# RL6842_IP_SVD register map
Vendor: Realtek
IP svd file
Registers are 32-bit, read-write, reset 0x0 unless marked. A register's access mark holds for its fields unless they carry their own. Offsets are from the block's base; lines under a group give offsets from that group; [hi:lo] are bit positions; {n}, {i} and the like mark numbered series; 'fields as' and 'values as' point back to an identical list; <NAME> marks a mode.

## Memory map
0x40000000 PAGE0 size 0x100
0x40000000 PAGE1 size 0x1200
0x40000000 PAGE2 size 0x300
0x40000000 PAGE3 size 0x1310
0x40000000 PAGE4 size 0x14A4
0x40000000 PAGE5 size 0x15AC
0x40000000 PAGE6 size 0x1700
0x40000000 PAGE7 size 0x800
0x40000000 PAGE12 size 0x1300
0x40000000 PAGE17 size 0x1800
0x40000000 PAGE26 size 0x2620
0x40000000 TXPWR_CTRL size 0xDB04
0x40100000 AES_REG size 0x101C
0x40108000 SHA_REG size 0x101C
0x40110000 GDMA0_REG size 0x400
0x40118000 SPI0_REG size 0xB0C
0x40119000 SPI1_REG size 0xB0C
0x4011A000 I2C0_REG size 0x100
0x4011B000 I2C1_REG size 0x100
0x4011C000 SPORT0_REG size 0x984
0x4011D000 SPORT1_REG size 0x984
0x4011E000 DEBUGTIMER_REG size 0x18
0x4011F000 ECDSA_REG size 0x204
0x41000000 OTPC_REG size 0x744
0x41008000 PSRAM_PHY_REG size 0xFC
0x41009000 PSRAM_REG size 0x1D4
0x4100A000 SPI_FLASH_CTRL size 0x1D4
0x4100C000 LP_AON size 0x100
0x4100C100 REGU size 0x80
0x4100C200 LP_SYS size 0x100
0x4100C300 PMC size 0x64
0x4100C400 XTAL size 0x40
0x4100C440 PLL size 0x38
0x4100C480 WLAFE size 0x40
0x4100C600 MEMX size 0x200
0x4100C800 PINMUX_REG size 0x1FC
0x4100CA00 RSIP_REG size 0x160
0x4100CC00 WDG0_REG size 0x14
0x41010000 UART0_REG size 0x60
0x41011000 UART1_REG size 0x60
0x41012000 UART2_REG size 0x60
0x41013000 UART3_REG size 0x60
0x41014000 UARTLOG_REG size 0x78
0x41015000 LEDC_REG size 0xF8
0x41016000 TRNG_REG size 0x1BC
0x41017000 AUDIO_REG size 0x908
{0x41018000+0x200*n} TIMER{n}_REG size 0x88 (n=0..14)
0x4101A000 GPIO_REG size 0x100
0x4101B000 RTC size 0x2C
0x4101C000 ADC_REG size 0xB4
0x4101C800 CMP_REG size 0x58
0x4101D000 THERMAL_REG size 0x34
0x4101E000 CTC_REG size 0x418
0x4101F000 WDG1_REG size 0x14
0x4101F040 WDG2_REG size 0x14
0x4101F080 WDG3_REG size 0x14
0x4101F0C0 WDG4_REG size 0x14
0x41020000 IPC0_REG size 0x28
0x41020080 IPC1_REG size 0x28
0x41020100 IPC2_REG size 0x28
0x41021000 SDM_REG size 0x24
0x41022100 AUD_SYS_REG size 0x30
0x42000000 ZGB size 0x28

## SDM_REG
Base 0x41021000
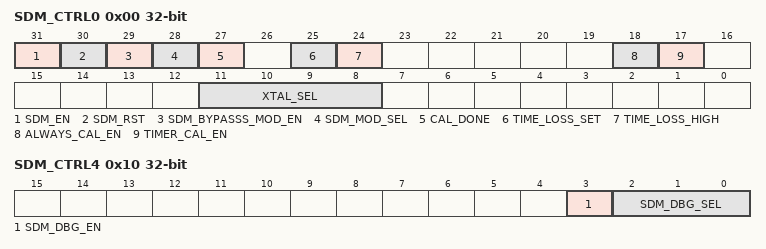
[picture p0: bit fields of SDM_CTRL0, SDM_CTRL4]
0x00 SDM_CTRL0 access per field — SDM Control Register
  [31] SDM_EN rw — Enable SDM
  [30] SDM_RST rw — 0: Reset SDM
  [29] SDM_BYPASSS_MOD_EN rw — Bypass mode enable
  [28] SDM_MOD_SEL rw — 0: Default mode 1: User-defined parameter mode
  [27] CAL_DONE ro
  [25] TIME_LOSS_SET rw — Time loss set 1: User-defined
  [24] TIME_LOSS_HIGH rw — Decide 32k output compensation direction 1: Mask 0: Add
  [18] ALWAYS_CAL_EN rw — 1: Enable always_cal
  [17] TIMER_CAL_EN rw — 1: Enable timer_cal
  [11:8] XTAL_SEL rw — XTAL frequency select, default 40M * 4'h0: XTAL40M * 4'h1: XTAL25M * 4'h4: XTAL20M * 4'h5: XTAL26M * 4'hD: XTAL27M * 4'hE: XTAL24M
0x04 SDM_CTRL1 — Config observed 128K cycle
  [15:0] SDM_OBS_CYC — Set observed 128k cycle, default 1024 128k cycles
0x08 SDM_CTRL2 — Set ref counter value
  [31:0] SDM_OBS_REF_CYC — Set in observed cycles, refer to counters value, default 312500 XTAL cycles
0x0C SDM_CTRL3 — Set XTAL period
  [31:0] XTAL_PERIOD — Set reference xtal period (ns)
0x10 SDM_CTRL4 — SDM Debug Register
  [3] SDM_DBG_EN — 1: Enable SDM debug
  [2:0] SDM_DBG_SEL — Set in observed cycles, refer to counters value
0x14 SDM_CTRL5 — Time loss Set
  [31:0] TIME_LOSS_REG — Source clock time loss every cycle
0x1C SDM_TIMEOUT reset 0x2000000 — Set Timer Trigger Counter Value
  [31:0] TIMEOUT_CNT — Set SDM timer trigger calibration timeout value
0x20 REG_SDM_DUMMY reset 0xFFFF — SDM Dummy Register

## PSRAM_PHY_REG
Base 0x41008000
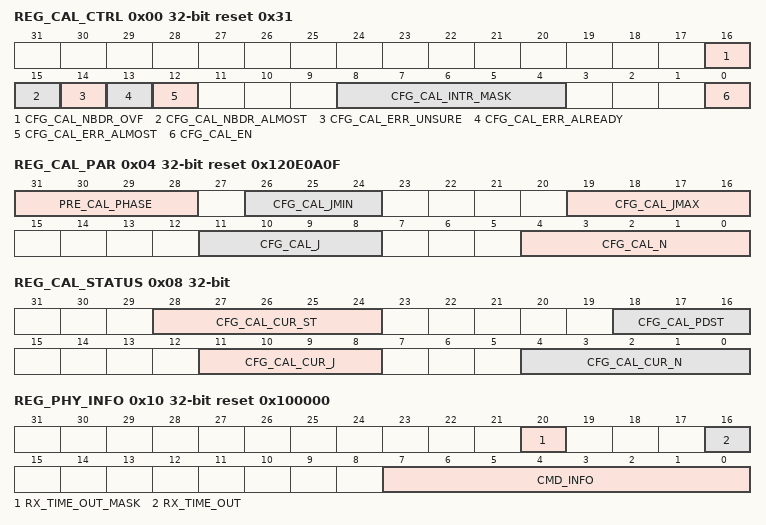
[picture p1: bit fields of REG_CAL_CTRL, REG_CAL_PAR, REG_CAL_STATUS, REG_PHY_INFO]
0x00 REG_CAL_CTRL access per field reset 0x31
  [16] CFG_CAL_NBDR_OVF ro — The N reachs the boundary , which is 0 or Nmax . Cleared by write 1 .
  [15] CFG_CAL_NBDR_ALMOST ro — The N-J or N+J reachs the boundary , which is 0 or Nmax . Cleared by write 1 .
  [14] CFG_CAL_ERR_UNSURE ro — The Pre N/J may cause current burst receive error , but it is not sure because the burst len is too small. Cleared by write 1 .
  [13] CFG_CAL_ERR_ALREADY ro — The Pre N/J may cause current burst receive error , even change J to Jmin , the error still remain . Cleared by write 1 .
  [12] CFG_CAL_ERR_ALMOST ro — The current burst receive correct , but next burst will set J = Jmin . Cleared by write 1 .
  [8:4] CFG_CAL_INTR_MASK rw — Calibration fail interrupt mask , every bit control one event above (1: enable , 0: disable) [0] : err almost [1] : err already [2] : err unsure [3] : nbdr almost [4] : nbdr ovf
  [0] CFG_CAL_EN rw — Hardware auto calibration enable , if disable , N,J will be fixed .
0x04 REG_CAL_PAR reset 0x120E0A0F
  [31:28] PRE_CAL_PHASE — one-hot phase select, 4-tap delay line to adjust rwds phase before calibration for large freq range or skew can be set to 0, bypassing the default 1-tap delay
  [26:24] CFG_CAL_JMIN — Minimum J . Hardware may adjust J , if J reach this value , an interrup will be raised to alerm software.
  [19:16] CFG_CAL_JMAX — Maximum J . Hardware may adjust J , but will not exceed this value.
  [11:8] CFG_CAL_J — Initial value J calibrated by software .
  [4:0] CFG_CAL_N — Initial value N calibrated by software .
0x08 REG_CAL_STATUS ro
  [28:24] CFG_CAL_CUR_ST — Calibration current state . Cleared by write all 1 .
  [18:16] CFG_CAL_PDST — Calibration check result for last read burst . [0] : indicate phase n+j , if 1 , means dn == dn+j [1] : indicate phase n-j , if 1 , means dn == dn-j [2] : if 1 , means the state is under j = jmin condition
  [11:8] CFG_CAL_CUR_J — Current value J read from hardware.
  [4:0] CFG_CAL_CUR_N — Current value N read from hardware.
0x10 REG_PHY_INFO access per field reset 0x100000
  [20] RX_TIME_OUT_MASK rw — read time out interrupt mask
  [16] RX_TIME_OUT ro — read time out interrupt if there's no DQS/DQ from psram, write 1 to clear
  [7:0] CMD_INFO ro — Command information, 1st Byte of Command/Address transaction
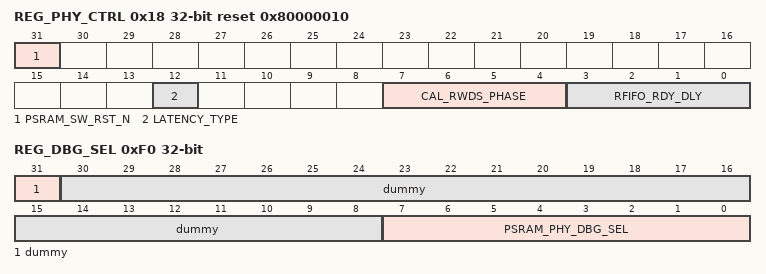
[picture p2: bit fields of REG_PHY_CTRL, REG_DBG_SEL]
0x18 REG_PHY_CTRL reset 0x80000010
  [31] PSRAM_SW_RST_N — low active, except for phy register(using system reset), psram software reset: psram, phy_ctrl, calibration
  [12] LATENCY_TYPE — set this bit according to spic & psram latency settings 0: variable latency 1: fixed latency
  [7:4] CAL_RWDS_PHASE — one-hot phase select, delay cal_rwds to push sampling data into rfifo
  [3:0] RFIFO_RDY_DLY — variable latency: delay read data cycles(phy clk) after detecting first DQS rising edge, must < 4 fixed latency: delay read data cycles(phy clk) after asserting spi_rx_data_en, recommend 4 ~ 6 4*read_latency - rd_dummy_length + rfifo_rdy_dly = in_physical_cyc
0xF0 REG_DBG_SEL
  [31] dummy — ECO: option to mask 1T psram clk at the end of first rdata block
  [30:8] dummy
  [7:0] PSRAM_PHY_DBG_SEL — psram phy debug select signal.
0xF8 REG_DBG_INFO ro
  [31:0] PSRAM_PHY_DBG — psram phy debug signals.

## Notices in the file
Copyright (C) 2012-2025 Realsil Limited. All rights reserved.
